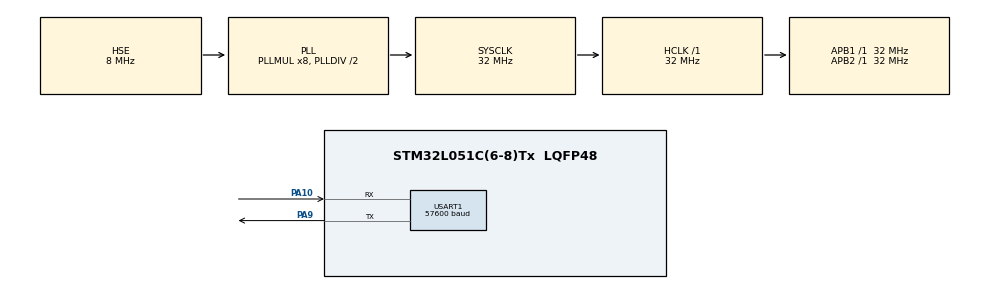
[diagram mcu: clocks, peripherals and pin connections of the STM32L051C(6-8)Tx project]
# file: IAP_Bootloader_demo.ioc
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Dma.Request0=USART1_RX
Dma.USART1_RX.0.Direction=DMA_PERIPH_TO_MEMORY
Dma.USART1_RX.0.Instance=DMA1_Channel3
Dma.USART1_RX.0.MemDataAlignment=DMA_MDATAALIGN_BYTE
Dma.USART1_RX.0.MemInc=DMA_MINC_ENABLE
Dma.USART1_RX.0.Mode=DMA_NORMAL
Dma.USART1_RX.0.PeriphDataAlignment=DMA_PDATAALIGN_BYTE
Dma.USART1_RX.0.PeriphInc=DMA_PINC_DISABLE
Dma.USART1_RX.0.Priority=DMA_PRIORITY_MEDIUM
Mcu.Family=STM32L0
Mcu.Name=STM32L051C(6-8)Tx
Mcu.Package=LQFP48
NVIC.USART1_IRQn=true\:0\:0\:true\:false\:true\:true\:true\:true
PA10.Mode=Asynchronous
PA10.Signal=USART1_RX
PA13.Mode=Serial_Wire
PA13.Signal=SYS_SWDIO
PA14.Mode=Serial_Wire
PA14.Signal=SYS_SWCLK
PA9.Mode=Asynchronous
PA9.Signal=USART1_TX
PH0-OSC_IN.Mode=HSE-External-Oscillator
PH0-OSC_IN.Signal=RCC_OSC_IN
PH1-OSC_OUT.Mode=HSE-External-Oscillator
PH1-OSC_OUT.Signal=RCC_OSC_OUT
ProjectManager.HeapSize=0x200
ProjectManager.StackSize=0x400
ProjectManager.TargetToolchain=MDK-ARM V5.32
RCC.AHBFreq_Value=32000000
RCC.APB1Freq_Value=32000000
RCC.APB1TimFreq_Value=32000000
RCC.APB2Freq_Value=32000000
RCC.APB2TimFreq_Value=32000000
RCC.HCLKFreq_Value=32000000
RCC.HSE_VALUE=8000000
RCC.HSI16_VALUE=16000000
RCC.HSI_VALUE=16000000
RCC.LSE_VALUE=32768
RCC.MSI_VALUE=2097000
RCC.PLLMUL=RCC_PLLMUL_8
RCC.PLLSourceVirtual=RCC_PLLSOURCE_HSE
RCC.SYSCLKFreq_VALUE=32000000
RCC.SYSCLKSource=RCC_SYSCLKSOURCE_PLLCLK
RCC.VCOOutputFreq_Value=64000000
TIM6.AutoReloadPreload=TIM_AUTORELOAD_PRELOAD_DISABLE
TIM6.Period=0xffff
TIM6.Prescaler=32000-1
USART1.BaudRate=57600
USART1.VirtualMode-Asynchronous=VM_ASYNC
VP_RTC_VS_RTC_Activate.Mode=RTC_Enabled
VP_TIM6_VS_ClockSourceINT.Mode=Enable_Timer
board=custom

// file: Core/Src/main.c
/* USER CODE BEGIN Header */
/*
 *                   ___====-_  _-====___
 *             _--^^^#####//      \\#####^^^--_
 *          _-^##########// (    ) \\##########^-_
 *         -############//  |\^^/|  \\############-
 *       _/############//   (@::@)   \############\_
 *      /#############((     \\//     ))#############\
 *     -###############\\    (oo)    //###############-
 *    -#################\\  / VV \  //#################-
 *   -###################\\/      \//###################-
 *  _#/|##########/\######(   /\   )######/\##########|\#_
 *  |/ |#/\#/\#/\/  \#/\##\  |  |  /##/\#/  \/\#/\#/\#| \|
 *  `  |/  V  V  `   V  \#\| |  | |/#/  V   '  V  V  \|  '
 *     `   `  `      `   / | |  | | \   '      '  '   '
 *                      (  | |  | |  )
 *                     __\ | |  | | /__
 *                    (vvv(VVV)(VVV)vvv)
 *
 *      ~~~~~~~~~~~~~~~~~~~~~~~~~~~~~~~~~~~~~~~~~~~
 *
 *                神兽保佑            永无BUG
 */
/**
  ******************************************************************************
  * @file           : main.c
  * @brief          : Main program body
  ******************************************************************************
  * @attention
  *
  * Copyright (c) 2024 STMicroelectronics.
  * All rights reserved.
  *
  * This software is licensed under terms that can be found in the LICENSE file
  * in the root directory of this software component.
  * If no LICENSE file comes with this software, it is provided AS-IS.
  *
  ******************************************************************************
  */
/* USER CODE END Header */
#include "main.h"
#include "dma.h"
#include "rtc.h"
#include "tim.h"
#include "usart.h"
#include "gpio.h"

/* USER CODE BEGIN Includes */
#include "stdio.h"
#include "flash.h"
#include "iap_bootloader.h"
/* USER CODE END Includes */

/* USER CODE BEGIN PV */
uint8_t uart1RxBuff[UART1RXBUFFSIZE] = {0};
/* USER CODE END PV */

void SystemClock_Config(void);

/* USER CODE BEGIN 0 */
/**
 * @description: 串口printf重定向
 * @param {int} ch
 * @param {FILE} *f
 * @return {*}
 */
int fputc(int ch, FILE *f)
{
  HAL_UART_Transmit(&huart1, (uint8_t *)&ch, 1, HAL_MAX_DELAY);
  return ch;
}
/* USER CODE END 0 */

int main(void)
{

  /* MCU Configuration--------------------------------------------------------*/

  /* Reset of all peripherals, Initializes the Flash interface and the Systick. */
  HAL_Init();

  /* Configure the system clock */
  SystemClock_Config();

  /* Initialize all configured peripherals */
  MX_GPIO_Init();
  MX_DMA_Init();
  MX_USART1_UART_Init();
  MX_TIM6_Init();
  MX_RTC_Init();
  /* USER CODE BEGIN 2 */
  /*读取备份寄存器 检查是否有更新请求*/
  /*若备份寄存器的值为设定值 则进入bootloader*/
  if(HAL_RTCEx_BKUPRead(&hrtc,RTC_BKP_DR0) == OTA_REQ_FLAG)
  {
    /*终端打印菜单*/

    printf("\r\n **********************************************");
    printf("\r\n ***      STM32  IAP BOOTLOADER             ***");
    printf("\r\n ***                  Verson 1.0 By Tomood  ***");
    printf("\r\n **********************************************");
    printf("\r\n");
    /*启动串口接收*/
    HAL_UARTEx_ReceiveToIdle_DMA(&huart1, (uint8_t*)&uart1RxBuff, UART1RXBUFFSIZE);
    // /*关闭dma半满中断 如果打开了DMA中断的时候要关这个 防止DMA半满中断影响IDLE中断判断*/
    // __HAL_DMA_DISABLE_IT(&hdma_usart1_rx, DMA_IT_HT);
    /*等待发送程序包*/
    printf("\r\nPlease send .bin file (less than %dbyte) to STM32 ...\r\n", UART1RXBUFFSIZE);
    /*主程序卡住等中断处理*/
    while (1);
  }
  /*无更新请求时正常启动*/
  else
  {
    /*跳转到app程序段正常执行*/
    iap_load_app(APPLICATION_ADDRESS);
  }
  /* USER CODE END 2 */

  /* Infinite loop */
  while (1)
  {

  }
}

void SystemClock_Config(void)
{
  RCC_OscInitTypeDef RCC_OscInitStruct = {0};
  RCC_ClkInitTypeDef RCC_ClkInitStruct = {0};
  RCC_PeriphCLKInitTypeDef PeriphClkInit = {0};

  /** Configure the main internal regulator output voltage
  */
  __HAL_PWR_VOLTAGESCALING_CONFIG(PWR_REGULATOR_VOLTAGE_SCALE1);

  /** Initializes the RCC Oscillators according to the specified parameters
  * in the RCC_OscInitTypeDef structure.
  */
  RCC_OscInitStruct.OscillatorType = RCC_OSCILLATORTYPE_LSI|RCC_OSCILLATORTYPE_HSE;
  RCC_OscInitStruct.HSEState = RCC_HSE_ON;
  RCC_OscInitStruct.LSIState = RCC_LSI_ON;
  RCC_OscInitStruct.PLL.PLLState = RCC_PLL_ON;
  RCC_OscInitStruct.PLL.PLLSource = RCC_PLLSOURCE_HSE;
  RCC_OscInitStruct.PLL.PLLMUL = RCC_PLLMUL_8;
  RCC_OscInitStruct.PLL.PLLDIV = RCC_PLLDIV_2;
  if (HAL_RCC_OscConfig(&RCC_OscInitStruct) != HAL_OK)
  {
    Error_Handler();
  }

  /** Initializes the CPU, AHB and APB buses clocks
  */
  RCC_ClkInitStruct.ClockType = RCC_CLOCKTYPE_HCLK|RCC_CLOCKTYPE_SYSCLK
                              |RCC_CLOCKTYPE_PCLK1|RCC_CLOCKTYPE_PCLK2;
  RCC_ClkInitStruct.SYSCLKSource = RCC_SYSCLKSOURCE_PLLCLK;
  RCC_ClkInitStruct.AHBCLKDivider = RCC_SYSCLK_DIV1;
  RCC_ClkInitStruct.APB1CLKDivider = RCC_HCLK_DIV1;
  RCC_ClkInitStruct.APB2CLKDivider = RCC_HCLK_DIV1;

  if (HAL_RCC_ClockConfig(&RCC_ClkInitStruct, FLASH_LATENCY_1) != HAL_OK)
  {
    Error_Handler();
  }
  PeriphClkInit.PeriphClockSelection = RCC_PERIPHCLK_USART1|RCC_PERIPHCLK_RTC;
  PeriphClkInit.Usart1ClockSelection = RCC_USART1CLKSOURCE_PCLK2;
  PeriphClkInit.RTCClockSelection = RCC_RTCCLKSOURCE_LSI;
  if (HAL_RCCEx_PeriphCLKConfig(&PeriphClkInit) != HAL_OK)
  {
    Error_Handler();
  }
}

void Error_Handler(void)
{
  /* USER CODE BEGIN Error_Handler_Debug */
  /* User can add his own implementation to report the HAL error return state */
  //__disable_irq();
  printf("\r\nSys Err!\r\n");
  while (1)
  {
  }
  /* USER CODE END Error_Handler_Debug */
}
